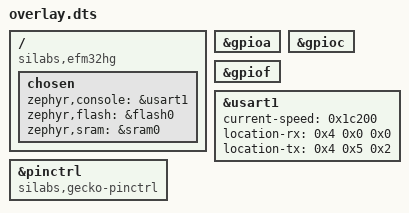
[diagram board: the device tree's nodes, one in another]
/ {
	compatible = "silabs,efm32hg", "silabs,efm32hg_slstk3400a";
	chosen {
		zephyr,console = &usart1;
		zephyr,flash = &flash0;
		zephyr,sram = &sram0;
	};
};
&gpioa{
	status = "okay";
};
&gpioc{
	status = "okay";
};
&gpiof{
	status = "okay";
};
&usart1{
	status = "okay";
	current-speed = < 0x1c200 >;
	location-rx = < 0x4 0x0 0x0 >;
	location-tx = < 0x4 0x5 0x2 >;
};
&pinctrl{
	compatible = "silabs,gecko-pinctrl";
};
